# STM32F042x6 register map
File version: 1.0
Registers are 32-bit, access not given, reset 0x0 unless marked. A register's access mark holds for its fields unless they carry their own. Offsets are from the block's base; [hi:lo] are bit positions; {n}, {i} and the like mark numbered series; 'fields as' and 'values as' point back to an identical list.

## CRS
Base 0x40006C00
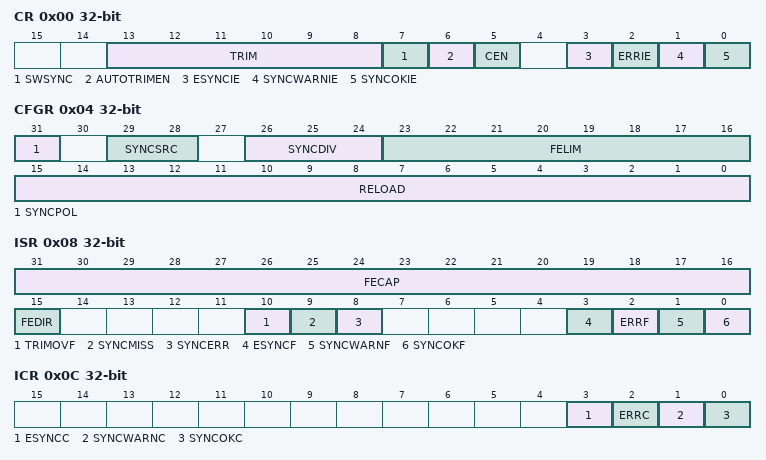
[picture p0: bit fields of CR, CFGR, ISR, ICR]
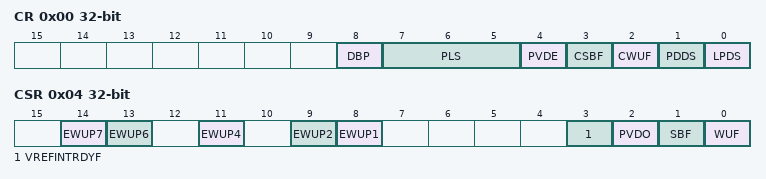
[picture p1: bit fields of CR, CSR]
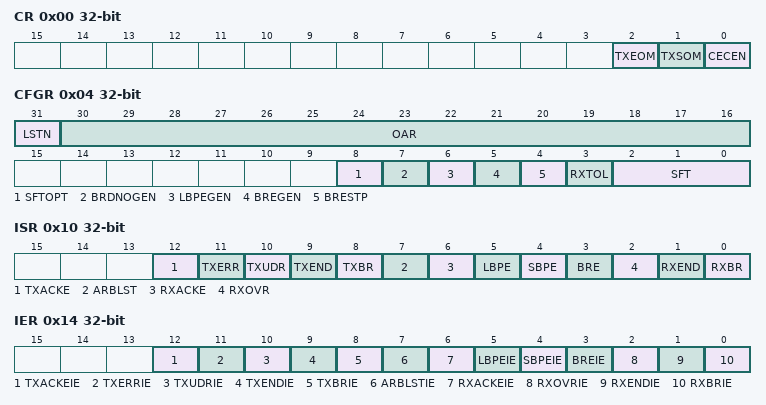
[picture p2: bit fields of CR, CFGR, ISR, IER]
0x00 CR
  [13:8] TRIM, [7] SWSYNC, [6] AUTOTRIMEN, [5] CEN, [3] ESYNCIE, [2] ERRIE, [1] SYNCWARNIE, [0] SYNCOKIE
0x04 CFGR
  [31] SYNCPOL, [29:28] SYNCSRC, [26:24] SYNCDIV, [23:16] FELIM, [15:0] RELOAD
0x08 ISR
  [31:16] FECAP, [15] FEDIR, [10] TRIMOVF, [9] SYNCMISS, [8] SYNCERR, [3] ESYNCF, [2] ERRF, [1] SYNCWARNF, [0] SYNCOKF
0x0C ICR
  [3] ESYNCC, [2] ERRC, [1] SYNCWARNC, [0] SYNCOKC

## PWR
Base 0x40007000
0x00 CR
  [8] DBP, [7:5] PLS, [4] PVDE, [3] CSBF, [2] CWUF, [1] PDDS, [0] LPDS
0x04 CSR
  [14] EWUP7, [13] EWUP6, [11] EWUP4, [9] EWUP2, [8] EWUP1, [3] VREFINTRDYF, [2] PVDO, [1] SBF, [0] WUF

## CEC
Base 0x40007800
0x00 CR
  [2] TXEOM, [1] TXSOM, [0] CECEN
0x04 CFGR
  [31] LSTN, [30:16] OAR, [8] SFTOPT, [7] BRDNOGEN, [6] LBPEGEN, [5] BREGEN, [4] BRESTP, [3] RXTOL, [2:0] SFT
0x08 TXDR
  [7:0] TXD
0x0C RXDR
0x10 ISR
  [12] TXACKE, [11] TXERR, [10] TXUDR, [9] TXEND, [8] TXBR, [7] ARBLST, [6] RXACKE, [5] LBPE, [4] SBPE, [3] BRE, [2] RXOVR, [1] RXEND, [0] RXBR
0x14 IER
  [12] TXACKEIE, [11] TXERRIE, [10] TXUDRIE, [9] TXENDIE, [8] TXBRIE, [7] ARBLSTIE, [6] RXACKEIE, [5] LBPEIE, [4] SBPEIE, [3] BREIE, [2] RXOVRIE, [1] RXENDIE, [0] RXBRIE

## SYSCFG
Base 0x40010000
0x00 CFGR1
  [23] I2C_FMP_PA10, [22] I2C_FMP_PA9, [21] I2C_FMP_I2C2, [20] I2C_FMP_I2C1, [n+10] I2C_FMP_PB{n} (n=6..9), [12] TIM17_DMA_RMP, [11] TIM16_DMA_RMP, [10] USART1RX_DMA_RMP, [9] USART1TX_DMA_RMP, [12:8] DMA_RMP, [4] PA11_PA12_RMP, [1:0] MEM_MODE
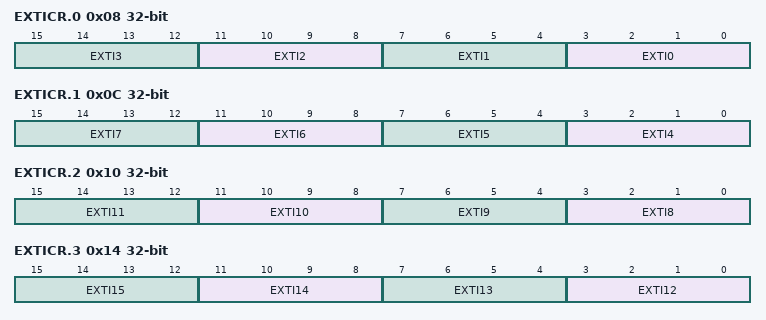
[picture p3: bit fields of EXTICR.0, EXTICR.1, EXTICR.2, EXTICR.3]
0x08 EXTICR.0
  [4n+3:4n] EXTI{n} (n=0..3)
0x0C EXTICR.1
  [4n-13:4n-16] EXTI{n} (n=4..7)
0x10 EXTICR.2
  [4n-29:4n-32] EXTI{n} (n=8..11)
0x14 EXTICR.3
  [4n-45:4n-48] EXTI{n} (n=12..15)
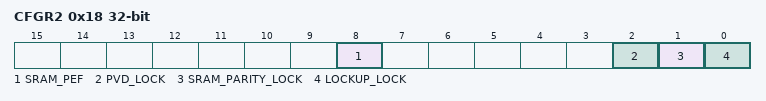
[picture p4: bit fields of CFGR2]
0x18 CFGR2
  [8] SRAM_PEF, [2] PVD_LOCK, [1] SRAM_PARITY_LOCK, [0] LOCKUP_LOCK

## EXTI
Base 0x40010400
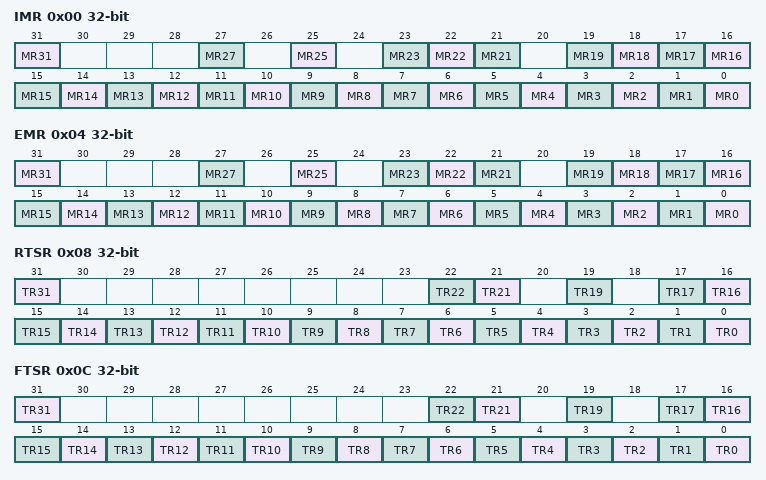
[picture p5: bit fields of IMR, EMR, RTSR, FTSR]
0x00 IMR
  [31] MR31, [27] MR27, [25] MR25, [23] MR23, [22] MR22, [21] MR21, [n] MR{n} (n=0..19)
0x04 EMR
  fields as IMR
0x08 RTSR
  [31] TR31, [22] TR22, [21] TR21, [19] TR19, [n] TR{n} (n=0..17)
0x0C FTSR
  [31] TR31, [22] TR22, [21] TR21, [19] TR19, [n] TR{n} (n=0..17)
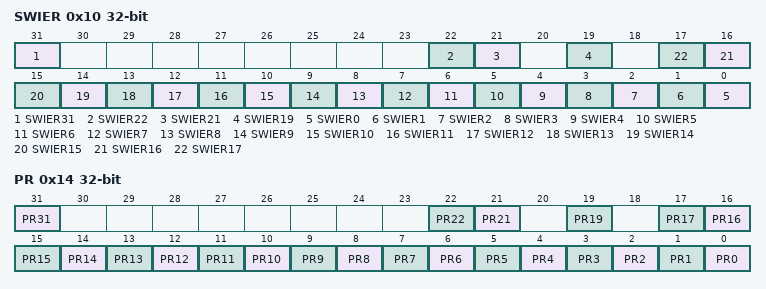
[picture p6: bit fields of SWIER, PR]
0x10 SWIER
  [31] SWIER31, [22] SWIER22, [21] SWIER21, [19] SWIER19, [n] SWIER{n} (n=0..17)
0x14 PR
  [31] PR31, [22] PR22, [21] PR21, [19] PR19, [n] PR{n} (n=0..17)

## ADC1
Base 0x40012400
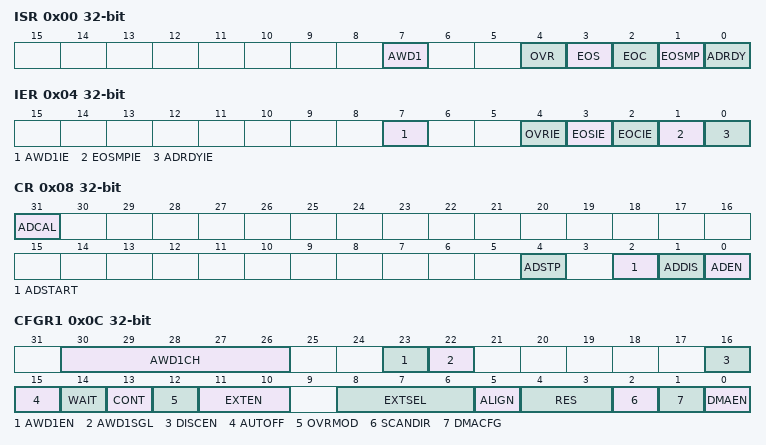
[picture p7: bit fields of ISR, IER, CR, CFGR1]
0x00 ISR
  [7] AWD1, [4] OVR, [3] EOS, [2] EOC, [1] EOSMP, [0] ADRDY
0x04 IER
  [7] AWD1IE, [4] OVRIE, [3] EOSIE, [2] EOCIE, [1] EOSMPIE, [0] ADRDYIE
0x08 CR
  [31] ADCAL, [4] ADSTP, [2] ADSTART, [1] ADDIS, [0] ADEN
0x0C CFGR1
  [30:26] AWD1CH, [23] AWD1EN, [22] AWD1SGL, [16] DISCEN, [15] AUTOFF, [14] WAIT, [13] CONT, [12] OVRMOD, [11:10] EXTEN, [8:6] EXTSEL, [5] ALIGN, [4:3] RES, [2] SCANDIR, [1] DMACFG, [0] DMAEN
0x10 CFGR2
  [31:30] CKMODE
0x14 SMPR
  [2:0] SMP
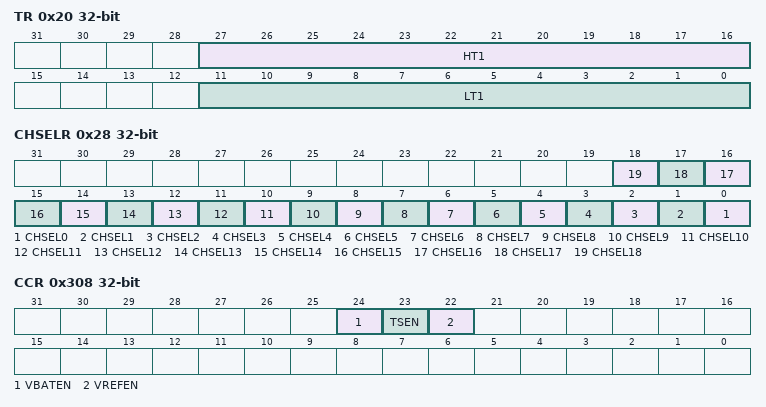
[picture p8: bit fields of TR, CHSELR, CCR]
0x20 TR
  [27:16] HT1, [11:0] LT1
0x28 CHSELR
  [n] CHSEL{n} (n=0..18)
0x40 DR
  [15:0] DATA
0x308 CCR
  [24] VBATEN, [23] TSEN, [22] VREFEN

## DBGMCU
Base 0x40015800
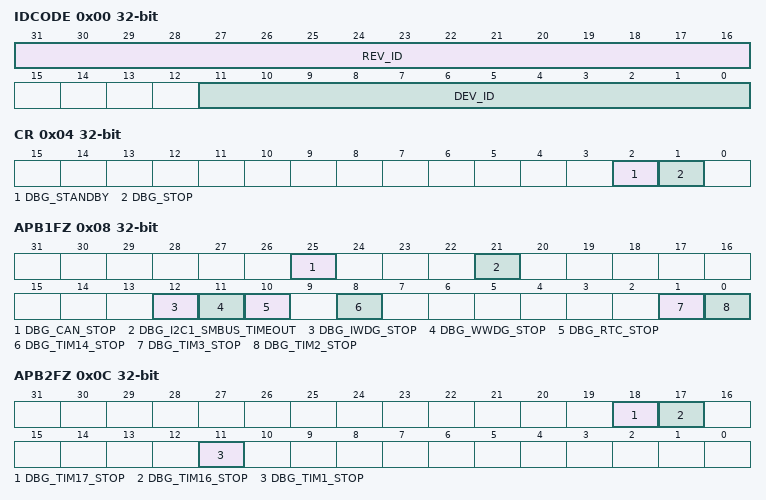
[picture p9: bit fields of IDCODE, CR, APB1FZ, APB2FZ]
0x00 IDCODE
  [31:16] REV_ID, [11:0] DEV_ID
0x04 CR
  [2] DBG_STANDBY, [1] DBG_STOP
0x08 APB1FZ
  [25] DBG_CAN_STOP, [21] DBG_I2C1_SMBUS_TIMEOUT, [12] DBG_IWDG_STOP, [11] DBG_WWDG_STOP, [10] DBG_RTC_STOP, [8] DBG_TIM14_STOP, [1] DBG_TIM3_STOP, [0] DBG_TIM2_STOP
0x0C APB2FZ
  [18] DBG_TIM17_STOP, [17] DBG_TIM16_STOP, [11] DBG_TIM1_STOP

## DMA1
Base 0x40020000
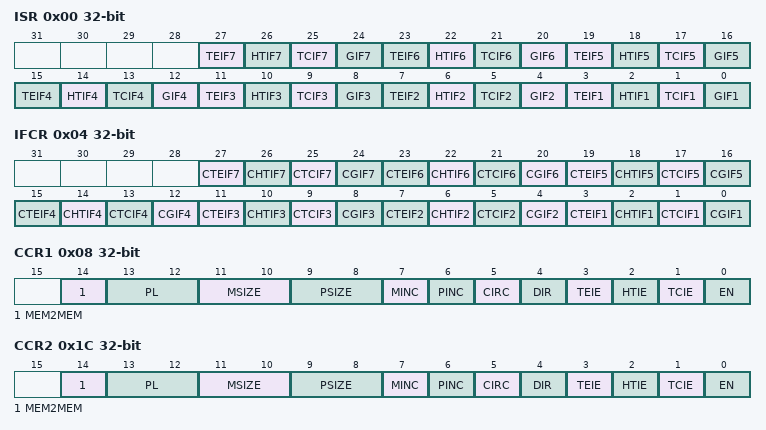
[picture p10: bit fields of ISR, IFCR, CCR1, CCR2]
0x00 ISR
  [4n-1] TEIF{n} (n=1..7), [4n-2] HTIF{n} (n=1..7), [4n-3] TCIF{n} (n=1..7), [4n-4] GIF{n} (n=1..7)
0x04 IFCR
  [4n-1] CTEIF{n} (n=1..7), [4n-2] CHTIF{n} (n=1..7), [4n-3] CTCIF{n} (n=1..7), [4n-4] CGIF{n} (n=1..7)
0x08 CCR1
  [14] MEM2MEM, [13:12] PL, [11:10] MSIZE, [9:8] PSIZE, [7] MINC, [6] PINC, [5] CIRC, [4] DIR, [3] TEIE, [2] HTIE, [1] TCIE, [0] EN
0x0C CNDTR1
  [15:0] NDT
{0x0+0x14*i} CPAR{i} (i=1..7)
  [31:0] PA
0x1C CCR2
  fields as CCR1
{0xC+0x14*i} CMAR{i} (i=1..7)
  [31:0] MA
0x20 CNDTR2
  [15:0] NDT
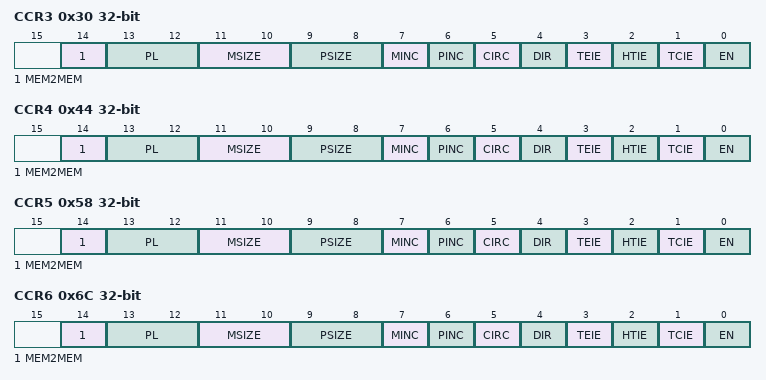
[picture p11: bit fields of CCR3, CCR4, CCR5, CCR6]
0x30 CCR3
  fields as CCR1
0x34 CNDTR3
  [15:0] NDT
0x44 CCR4
  fields as CCR1
0x48 CNDTR4
  [15:0] NDT
0x58 CCR5
  fields as CCR1
0x5C CNDTR5
  [15:0] NDT
0x6C CCR6
  fields as CCR1
0x70 CNDTR6
  [15:0] NDT
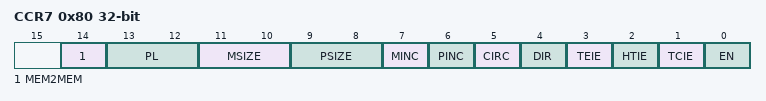
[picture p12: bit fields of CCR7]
0x80 CCR7
  fields as CCR1
0x84 CNDTR7
  [15:0] NDT
